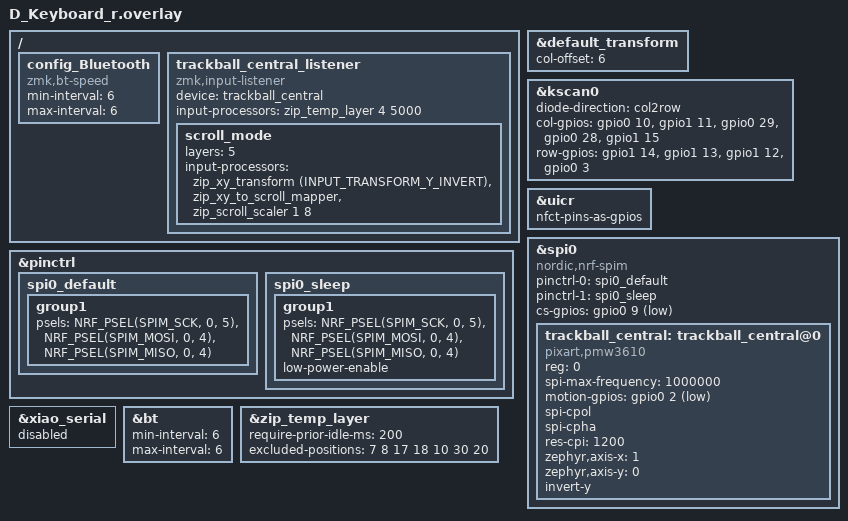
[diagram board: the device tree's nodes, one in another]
#include "D_Keyboard.dtsi"
#include <input/processors.dtsi>
#include <zephyr/dt-bindings/input/input-event-codes.h>
#include <dt-bindings/zmk/input_transform.h>
#include <behaviors.dtsi>
#include <dt-bindings/zmk/pointing.h>

&default_transform {
    col-offset = <6>;
};

&kscan0 {
//            row-gpios
//                = <&xiao_d 9 (GPIO_ACTIVE_HIGH | GPIO_PULL_DOWN)> 
//                , <&xiao_d 8 (GPIO_ACTIVE_HIGH | GPIO_PULL_DOWN)> 
//                , <&xiao_d 7 (GPIO_ACTIVE_HIGH | GPIO_PULL_DOWN)> 
//                , <&xiao_d 1 (GPIO_ACTIVE_HIGH | GPIO_PULL_DOWN)> 			
//                ;
//            col-gpios
//                = <&gpio0 10 GPIO_ACTIVE_HIGH>
//                , <&xiao_d 6 GPIO_ACTIVE_HIGH> 
//                , <&xiao_d 3 GPIO_ACTIVE_HIGH> 
//                , <&xiao_d 2 GPIO_ACTIVE_HIGH> 
//                , <&xiao_d 10 GPIO_ACTIVE_HIGH> 
//                ; 

diode-direction = "col2row";
    
    col-gpios
        = <&gpio0 10 GPIO_ACTIVE_HIGH> 
        , <&gpio1 11 GPIO_ACTIVE_HIGH> 
        , <&gpio0 29 GPIO_ACTIVE_HIGH> 
        , <&gpio0 28 GPIO_ACTIVE_HIGH> 
        , <&gpio1 15 GPIO_ACTIVE_HIGH> 
        ;

    row-gpios
        = <&gpio1 14 (GPIO_ACTIVE_HIGH | GPIO_PULL_DOWN)> 
        , <&gpio1 13 (GPIO_ACTIVE_HIGH | GPIO_PULL_DOWN)> 
        , <&gpio1 12 (GPIO_ACTIVE_HIGH | GPIO_PULL_DOWN)> 
        , <&gpio0 3  (GPIO_ACTIVE_HIGH | GPIO_PULL_DOWN)> 
        ;
};

&uicr {
        nfct-pins-as-gpios;
};

&pinctrl {
    spi0_default: spi0_default {    //通常時(SPI通信中)のピン構成
        group1 {
            psels = <NRF_PSEL(SPIM_SCK, 0, 5)>, //P0.05を指定(SCLK)
                <NRF_PSEL(SPIM_MOSI, 0, 4)>,    //P0.04を指定(SDIOだからMOSI,MISO両方の役割を担う)
                <NRF_PSEL(SPIM_MISO, 0, 4)>;
        };
    };

    spi0_sleep: spi0_sleep {    //スリープ時のピン構成(省電力)
        group1 {
            psels = <NRF_PSEL(SPIM_SCK, 0, 5)>,
                <NRF_PSEL(SPIM_MOSI, 0, 4)>,
                <NRF_PSEL(SPIM_MISO, 0, 4)>;
            low-power-enable;
        };
    };
};


&spi0 {
    status = "okay";
    compatible = "nordic,nrf-spim"; //マイコンがnRFシリーズ
    pinctrl-0 = <&spi0_default>;
    pinctrl-1 = <&spi0_sleep>;
    pinctrl-names = "default", "sleep";
    cs-gpios = <&gpio0 9 GPIO_ACTIVE_LOW>; /* CS (回路図 0.09) */

    trackball_central: trackball_central@0 {
        status = "okay";
        compatible = "pixart,pmw3610";  //トラボセンサ用のドライバとバインド
        reg = <0>;
//        smart-mode;
        spi-max-frequency = <1000000>;
        motion-gpios = <&gpio0 2 (GPIO_ACTIVE_LOW | GPIO_PULL_UP)>; /* MOTION (回路図 0.02) */
        spi-cpol;
        spi-cpha;
        res-cpi = <1200>;
        zephyr,axis-x = <1>;  // 0 = X軸
        zephyr,axis-y = <0>;  // 1 = Y軸
        invert-y;
    };
};

&xiao_serial {
    status = "disabled";
};

/* Bluetoothの通信間隔を最短(7.5ms)に設定 */
&bt {
    min-interval = <6>;
    max-interval = <6>;
};

&zip_temp_layer {
    require-prior-idle-ms = <200>;
    excluded-positions = <
        7 // i
        8 // o
        17 // k
        18 // l
        10 // Ctrl
        30 // Ctrl
        20 // Shift
    >;
};

/ {
/* 通信設定をデバイスツリーに明示的に追加 */
    config_Bluetooth {
        compatible = "zmk,bt-speed";
        min-interval = <6>;
        max-interval = <6>;
    };

trackball_central_listener: trackball_central_listener {
        compatible = "zmk,input-listener";
        status = "okay";
        device = <&trackball_central>;
        input-processors =
            <&zip_temp_layer 4 5000>;                       //オートマウスレイヤーの選択
 
        scroll_mode {
            layers = <5>;
            input-processors =
                <&zip_xy_transform (INPUT_TRANSFORM_Y_INVERT)>,
                <&zip_xy_to_scroll_mapper>,
                <&zip_scroll_scaler 1 8>;
        };
    };
};
